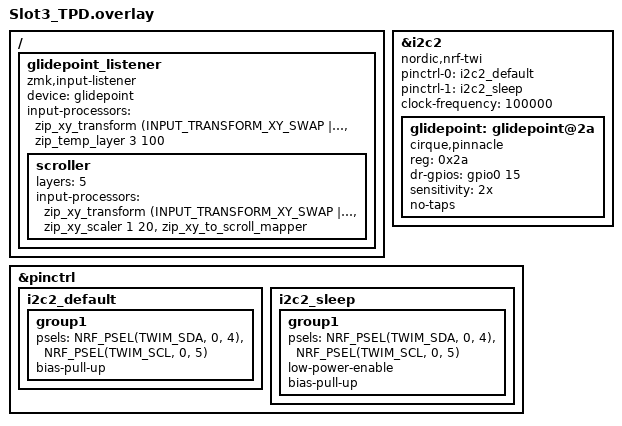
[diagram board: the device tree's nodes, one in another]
#include <dt-bindings/zmk/keys.h>
#include <dt-bindings/zmk/pointing.h>

&i2c2 {
    status = "okay";
    compatible = "nordic,nrf-twi";
    pinctrl-0 = <&i2c2_default>;
    pinctrl-1 = <&i2c2_sleep>;
    pinctrl-names = "default", "sleep";
    clock-frequency = <100000>; 
    
    glidepoint: glidepoint@2a {
            compatible = "cirque,pinnacle";
            reg = <0x2a>;
            status = "okay";
            dr-gpios = <&gpio0 15 (GPIO_ACTIVE_HIGH)>;

            sensitivity = "2x";
            // sleep;
            no-taps;
        };
};

&pinctrl {    
    i2c2_default: i2c2_default {
        group1 {
            psels = <NRF_PSEL(TWIM_SDA, 0,  4)>,
                    <NRF_PSEL(TWIM_SCL, 0,  5)>;
            bias-pull-up;
        };
    };
      
    i2c2_sleep: i2c2_sleep {
        group1 {
            psels = <NRF_PSEL(TWIM_SDA, 0,  4)>,
                    <NRF_PSEL(TWIM_SCL, 0,  5)>;
            low-power-enable;
            bias-pull-up;
        };
    };
};

/ {
    glidepoint_listener: glidepoint_listener {
        compatible = "zmk,input-listener";
        status = "okay";
        device = <&glidepoint>;
        
        input-processors = <
            &zip_xy_transform (INPUT_TRANSFORM_XY_SWAP | INPUT_TRANSFORM_Y_INVERT)
            &zip_temp_layer 3 100
        >;

        scroller {
            layers = <5>;
            input-processors = <
                &zip_xy_transform (INPUT_TRANSFORM_XY_SWAP | INPUT_TRANSFORM_X_INVERT)
                &zip_xy_scaler 1 20
                &zip_xy_to_scroll_mapper
            >;
        };
    };
};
